# ATtiny2313A register map
Vendor: Atmel; File version: 1.0
CPU: other r0p0, little endian, no MPU, no FPU, 4 interrupt priority bits
Registers are 8-bit, read-write, reset 0x0 unless marked. A register's access mark holds for its fields unless they carry their own. Offsets are from the block's base; [hi:lo] are bit positions.

## EEPROM
Base 0x0080003C
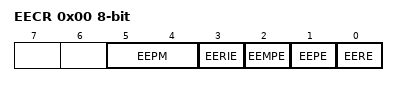
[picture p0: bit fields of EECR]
0x00 EECR — EEPROM Control Register
  [5:4] EEPM
    0=ERASE_AND_WRITE_IN_ONE_OPERATION; 1=ERASE_ONLY; 2=WRITE_ONLY
  [3] EERIE — EEProm Ready Interrupt Enable
  [2] EEMPE — EEPROM Master Write Enable
  [1] EEPE — EEPROM Write Enable
  [0] EERE — EEPROM Read Enable
0x01 EEDR — EEPROM Data Register
0x02 EEAR — EEPROM Read/Write Access

## EXINT — External Interrupts
Base 0x00800024
0x00 PCMSK1 — Pin Change Interrupt Mask Register 1 (read-only for debugger)
  [2:0] PCINT — Pin Change Interrupt Masks
0x01 PCMSK2 — Pin Change Interrupt Mask Register 2 (read-only for debugger)
  [6:0] PCINT — Pin Change Interrupt Masks
0x1C PCMSK0 — Pin Change Interrupt Mask Register 0
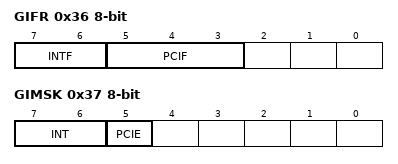
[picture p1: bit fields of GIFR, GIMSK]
0x36 GIFR — General Interrupt Flag Register (read-only for debugger)
  [7:6] INTF — External Interrupt Flags
  [5:3] PCIF — Pin Change Interrupt Flags
0x37 GIMSK — General Interrupt Mask Register
  [7:6] INT — External Interrupt Request 1 Enable
  [5] PCIE

## PORTA — I/O Port
Base 0x00800039
0x00 PINA — Port A Input Pins (read-only for debugger)
0x01 DDRA — Port A Data Direction Register
0x02 PORTA — Port A Data Register

## PORTB — I/O Port
Base 0x00800036
0x00 PINB — Port B Input Pins (read-only for debugger)
0x01 DDRB — Port B Data Direction Register
0x02 PORTB — Port B Data Register

## PORTD — I/O Port
Base 0x00800030
0x00 PIND — Input Pins, Port D (read-only for debugger)
0x01 DDRD — Data Direction Register, Port D
0x02 PORTD — Data Register, Port D

## TC0 — Timer/Counter, 8-bit
Base 0x00800050
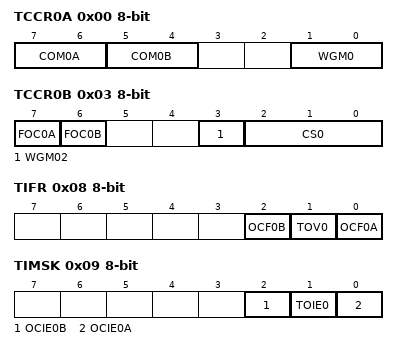
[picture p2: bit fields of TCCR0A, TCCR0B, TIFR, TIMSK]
0x00 TCCR0A — Timer/Counter Control Register A
  [7:6] COM0A — Compare Match Output A Mode
  [5:4] COM0B — Compare Match Output B Mode
  [1:0] WGM0 — Waveform Generation Mode
0x02 TCNT0 — Timer/Counter0
0x03 TCCR0B — Timer/Counter Control Register B
  [7] FOC0A — Force Output Compare B
  [6] FOC0B — Force Output Compare B
  [3] WGM02
  [2:0] CS0 — Clock Select
    0=NO_CLOCK_SOURCE_STOPPED; 1=RUNNING_NO_PRESCALING; 2=RUNNING_CLK_8; 3=RUNNING_CLK_64; 4=RUNNING_CLK_256; 5=RUNNING_CLK_1024; 6=RUNNING_EXTCLK_TN_FALLING_EDGE; 7=RUNNING_EXTCLK_TN_RISING_EDGE
0x06 OCR0A — Timer/Counter0 Output Compare Register
0x08 TIFR — Timer/Counter Interrupt Flag register (read-only for debugger)
  [2] OCF0B — Timer/Counter0 Output Compare Flag 0B
  [1] TOV0 — Timer/Counter0 Overflow Flag
  [0] OCF0A — Timer/Counter0 Output Compare Flag 0A
0x09 TIMSK — Timer/Counter Interrupt Mask Register
  [2] OCIE0B — Timer/Counter0 Output Compare Match B Interrupt Enable
  [1] TOIE0 — Timer/Counter0 Overflow Interrupt Enable
  [0] OCIE0A — Timer/Counter0 Output Compare Match A Interrupt Enable
0x0C OCR0B — Timer/Counter0 Output Compare Register

## TC1 — Timer/Counter, 16-bit
Base 0x00800042
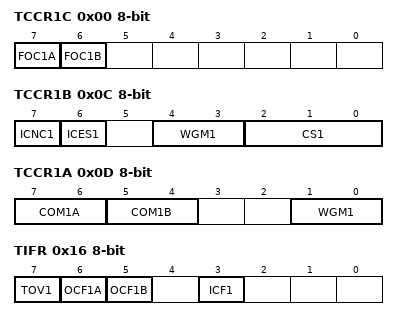
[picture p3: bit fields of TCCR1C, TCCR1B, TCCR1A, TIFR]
0x00 TCCR1C — Timer/Counter1 Control Register C (read-only for debugger)
  [7] FOC1A — Force Output Compare for Channel A
  [6] FOC1B — Force Output Compare for Channel B
0x02 ICR1 16-bit (reset mask 0xFF) — Timer/Counter1 Input Capture Register Bytes
0x06 OCR1B 16-bit (reset mask 0xFF) — Timer/Counter1 Output Compare Register Bytes
0x08 OCR1A 16-bit (reset mask 0xFF) — Timer/Counter1 Output Compare Register Bytes
0x0A TCNT1 16-bit (reset mask 0xFF) — Timer/Counter1 Bytes
0x0C TCCR1B — Timer/Counter1 Control Register B
  [7] ICNC1 — Input Capture 1 Noise Canceler
  [6] ICES1 — Input Capture 1 Edge Select
  [4:3] WGM1 — Waveform Generation Mode Bits
  [2:0] CS1 — Clock Select1 bits
    0=NO_CLOCK_SOURCE_STOPPED; 1=RUNNING_NO_PRESCALING; 2=RUNNING_CLK_8; 3=RUNNING_CLK_64; 4=RUNNING_CLK_256; 5=RUNNING_CLK_1024; 6=RUNNING_EXTCLK_TN_FALLING_EDGE; 7=RUNNING_EXTCLK_TN_RISING_EDGE
0x0D TCCR1A — Timer/Counter1 Control Register A
  [7:6] COM1A — Compare Output Mode 1A, bits
  [5:4] COM1B — Compare Output Mode 1B, bits
  [1:0] WGM1 — Pulse Width Modulator Select Bits
0x16 TIFR — Timer/Counter Interrupt Flag register (read-only for debugger)
  [7] TOV1 — Timer/Counter1 Overflow Flag
  [6] OCF1A — Output Compare Flag 1A
  [5] OCF1B — Output Compare Flag 1B
  [3] ICF1 — Input Capture Flag 1
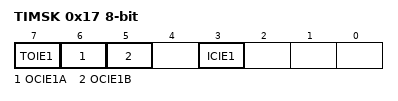
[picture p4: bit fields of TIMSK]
0x17 TIMSK — Timer/Counter Interrupt Mask Register
  [7] TOIE1 — Timer/Counter1 Overflow Interrupt Enable
  [6] OCIE1A — Timer/Counter1 Output CompareA Match Interrupt Enable
  [5] OCIE1B — Timer/Counter1 Output CompareB Match Interrupt Enable
  [3] ICIE1 — Timer/Counter1 Input Capture Interrupt Enable

## USART
Base 0x00800022
0x00 UBRRH — USART Baud Rate Register High Byte
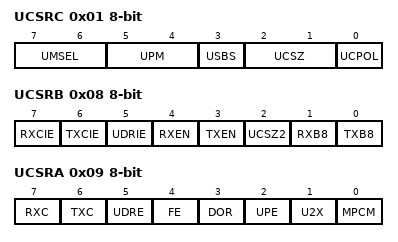
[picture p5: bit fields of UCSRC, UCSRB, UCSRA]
0x01 UCSRC — USART Control and Status Register C
  [7:6] UMSEL — USART Mode Select
    0=ASYNCHRONOUS_OPERATION; 1=SYNCHRONOUS_OPERATION; 3=MASTER_SPI
  [5:4] UPM — Parity Mode Bits
    0=DISABLED; 2=ENABLED_EVEN_PARITY; 3=ENABLED_ODD_PARITY
  [3] USBS — Stop Bit Select
    0=1_BIT; 1=2_BIT
  [2:1] UCSZ — Character Size Bits
  [0] UCPOL — Clock Polarity
0x07 UBRRL — USART Baud Rate Register Low Byte
0x08 UCSRB — USART Control and Status Register B
  [7] RXCIE — RX Complete Interrupt Enable
  [6] TXCIE — TX Complete Interrupt Enable
  [5] UDRIE — USART Data register Empty Interrupt Enable
  [4] RXEN — Receiver Enable
  [3] TXEN — Transmitter Enable
  [2] UCSZ2 — Character Size
  [1] RXB8 — Receive Data Bit 8
  [0] TXB8 — Transmit Data Bit 8
0x09 UCSRA — USART Control and Status Register A (read-only for debugger)
  [7] RXC ro — USART Receive Complete
  [6] TXC — USART Transmit Complete
  [5] UDRE ro — USART Data Register Empty
  [4] FE ro — Framing Error
  [3] DOR ro — Data Overrun
  [2] UPE ro — USART Parity Error
  [1] U2X — Double the USART Transmission Speed
  [0] MPCM — Multi-processor Communication Mode
0x0A UDR — USART I/O Data Register (write-only for debugger)

## USI — Universal Serial Interface
Base 0x0080002D
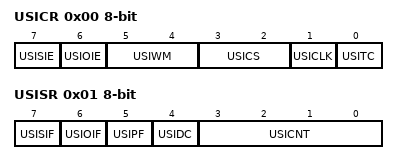
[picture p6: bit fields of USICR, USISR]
0x00 USICR — USI Control Register
  [7] USISIE — Start Condition Interrupt Enable
  [6] USIOIE — Counter Overflow Interrupt Enable
  [5:4] USIWM — USI Wire Mode Bits
    0=NORMAL_OPERATION; 1=THREE_WIRE_MODE; 2=TWO_WIRE_MODE; 3=TWO_WIRE_MODE_HELD_LOW
  [3:2] USICS — USI Clock Source Select Bits
  [1] USICLK — Clock Strobe
  [0] USITC — Toggle Clock Port Pin
0x01 USISR — USI Status Register (read-only for debugger)
  [7] USISIF — Start Condition Interrupt Flag
  [6] USIOIF — Counter Overflow Interrupt Flag
  [5] USIPF — Stop Condition Flag
  [4] USIDC — Data Output Collision
  [3:0] USICNT — USI Counter Value Bits
0x02 USIDR — USI Data Register

## WDT — Watchdog Timer
Base 0x00800041
0x00 WDTCR — Watchdog Timer Control Register (read-only for debugger)
  [7] WDIF — Watchdog Timeout Interrupt Flag
  [6] WDIE — Watchdog Timeout Interrupt Enable
  [4] WDCE — Watchdog Change Enable
  [3] WDE — Watch Dog Enable
  [5:0] WDP — Watchdog Timer Prescaler Bits
    0=OSCILLATOR_CYCLES_2K; 1=OSCILLATOR_CYCLES_4K; 2=OSCILLATOR_CYCLES_8K; 3=OSCILLATOR_CYCLES_16K; 4=OSCILLATOR_CYCLES_32K; 5=OSCILLATOR_CYCLES_64K; 6=OSCILLATOR_CYCLES_128K; 7=OSCILLATOR_CYCLES_256K
